# STM32L053x register map
File version: 1.0
Registers are 32-bit, read-write, reset 0x0 unless marked. A register's access mark holds for its fields unless they carry their own. Offsets are from the block's base; [hi:lo] are bit positions; lines under a group give offsets from that group; {n}, {i} and the like mark numbered series; 'fields as' and 'values as' point back to an identical list.

## LCD — Liquid crystal display controller
Base 0x40002400
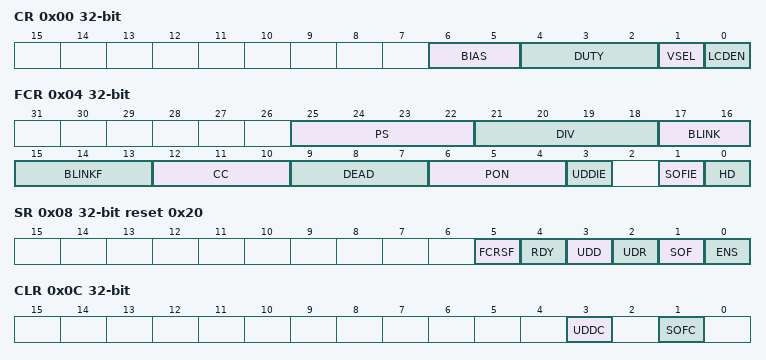
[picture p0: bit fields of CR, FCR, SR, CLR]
0x00 CR — control register
  [6:5] BIAS — Bias selector
  [4:2] DUTY — Duty selection
  [1] VSEL — Voltage source selection
  [0] LCDEN — LCD controller enable
0x04 FCR — frame control register
  [25:22] PS — PS 16-bit prescaler
  [21:18] DIV — DIV clock divider
  [17:16] BLINK — Blink mode selection
  [15:13] BLINKF — Blink frequency selection
  [12:10] CC — Contrast control
  [9:7] DEAD — Dead time duration
  [6:4] PON — Pulse ON duration
  [3] UDDIE — Update display done interrupt enable
  [1] SOFIE — Start of frame interrupt enable
  [0] HD — High drive enable
0x08 SR access per field reset 0x20 — status register
  [5] FCRSF ro — LCD Frame Control Register Synchronization flag
  [4] RDY ro — Ready flag
  [3] UDD ro — Update Display Done
  [2] UDR wo — Update display request
  [1] SOF ro — Start of frame flag
  [0] ENS ro
0x0C CLR wo — clear register
  [3] UDDC — Update display done clear
  [1] SOFC — Start of frame flag clear
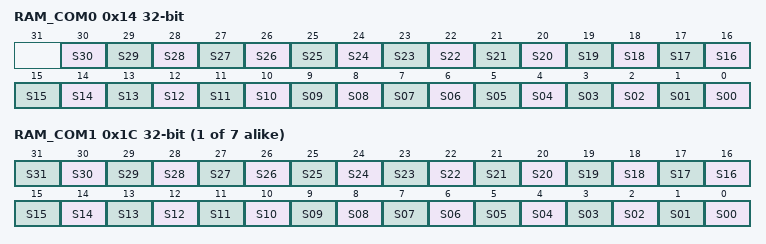
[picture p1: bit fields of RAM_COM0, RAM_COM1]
0x14 RAM_COM0 — display memory
  [n] S{n:02} (n=0..30)
{0x14+8i} RAM_COM{i} (i=1..7) — display memory
  [n] S{n:02} (n=0..31)

## LPTIM — Low power timer
Base 0x40007C00
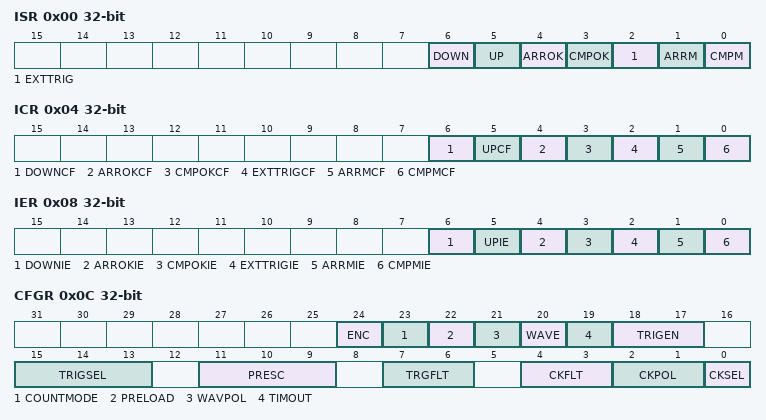
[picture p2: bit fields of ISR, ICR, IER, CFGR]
0x00 ISR ro — Interrupt and Status Register
  [6] DOWN — Counter direction change up to down
  [5] UP — Counter direction change down to up
  [4] ARROK — Autoreload register update OK
  [3] CMPOK — Compare register update OK
  [2] EXTTRIG — External trigger edge event
  [1] ARRM — Autoreload match
  [0] CMPM — Compare match
0x04 ICR wo — Interrupt Clear Register
  [6] DOWNCF — Direction change to down Clear Flag
  [5] UPCF — Direction change to UP Clear Flag
  [4] ARROKCF — Autoreload register update OK Clear Flag
  [3] CMPOKCF — Compare register update OK Clear Flag
  [2] EXTTRIGCF — External trigger valid edge Clear Flag
  [1] ARRMCF — Autoreload match Clear Flag
  [0] CMPMCF — compare match Clear Flag
0x08 IER — Interrupt Enable Register
  [6] DOWNIE — Direction change to down Interrupt Enable
  [5] UPIE — Direction change to UP Interrupt Enable
  [4] ARROKIE — Autoreload register update OK Interrupt Enable
  [3] CMPOKIE — Compare register update OK Interrupt Enable
  [2] EXTTRIGIE — External trigger valid edge Interrupt Enable
  [1] ARRMIE — Autoreload match Interrupt Enable
  [0] CMPMIE — Compare match Interrupt Enable
0x0C CFGR — Configuration Register
  [24] ENC — Encoder mode enable
  [23] COUNTMODE — counter mode enabled
  [22] PRELOAD — Registers update mode
  [21] WAVPOL — Waveform shape polarity
  [20] WAVE — Waveform shape
  [19] TIMOUT — Timeout enable
  [18:17] TRIGEN — Trigger enable and polarity
  [15:13] TRIGSEL — Trigger selector
  [11:9] PRESC — Clock prescaler
  [7:6] TRGFLT — Configurable digital filter for trigger
  [4:3] CKFLT — Configurable digital filter for external clock
  [2:1] CKPOL — Clock Polarity
  [0] CKSEL — Clock selector
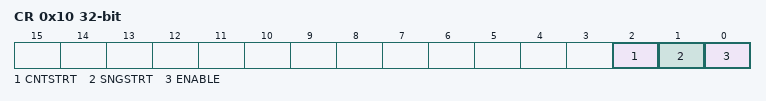
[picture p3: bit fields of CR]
0x10 CR — Control Register
  [2] CNTSTRT — Timer start in continuous mode
  [1] SNGSTRT — LPTIM start in single mode
  [0] ENABLE — LPTIM Enable
0x14 CMP — Compare Register
  [15:0] CMP — Compare value.
0x18 ARR reset 0x1 — Autoreload Register
  [15:0] ARR — Auto reload value.
0x1C CNT ro — Counter Register
  [15:0] CNT — Counter value.

## RNG — Random number generator
Base 0x40025000
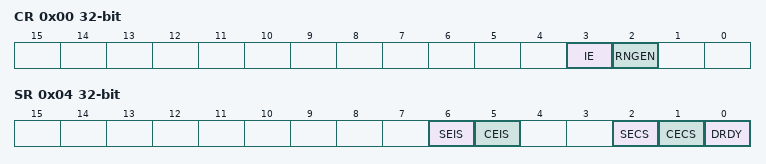
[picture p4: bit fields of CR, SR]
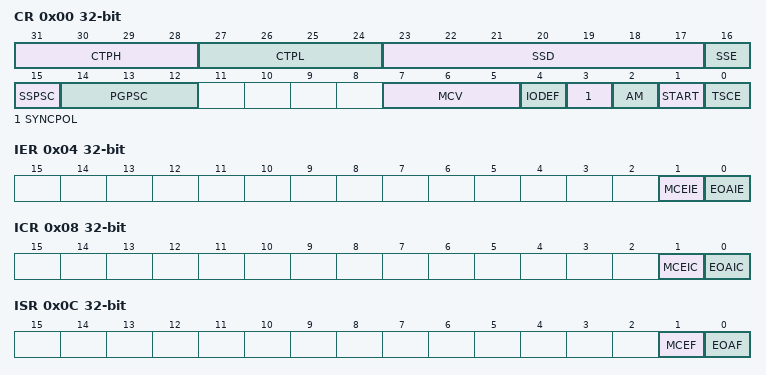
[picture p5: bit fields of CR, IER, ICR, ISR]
0x00 CR — control register
  [3] IE — Interrupt enable
  [2] RNGEN — Random number generator enable
0x04 SR access per field — status register
  [6] SEIS rw — Seed error interrupt status
  [5] CEIS rw — Clock error interrupt status
  [2] SECS ro — Seed error current status
  [1] CECS ro — Clock error current status
  [0] DRDY ro — Data ready
0x08 DR ro — data register
  [31:0] RNDATA — Random data

## TSC — Touch sensing controller
Base 0x40024000
0x00 CR — control register
  [31:28] CTPH — Charge transfer pulse high
  [27:24] CTPL — Charge transfer pulse low
  [23:17] SSD — Spread spectrum deviation
  [16] SSE — Spread spectrum enable
  [15] SSPSC — Spread spectrum prescaler
  [14:12] PGPSC — pulse generator prescaler
  [7:5] MCV — Max count value
  [4] IODEF — I/O Default mode
  [3] SYNCPOL — Synchronization pin polarity
  [2] AM — Acquisition mode
  [1] START — Start a new acquisition
  [0] TSCE — Touch sensing controller enable
0x04 IER — interrupt enable register
  [1] MCEIE — Max count error interrupt enable
  [0] EOAIE — End of acquisition interrupt enable
0x08 ICR — interrupt clear register
  [1] MCEIC — Max count error interrupt clear
  [0] EOAIC — End of acquisition interrupt clear
0x0C ISR — interrupt status register
  [1] MCEF — Max count error flag
  [0] EOAF — End of acquisition flag
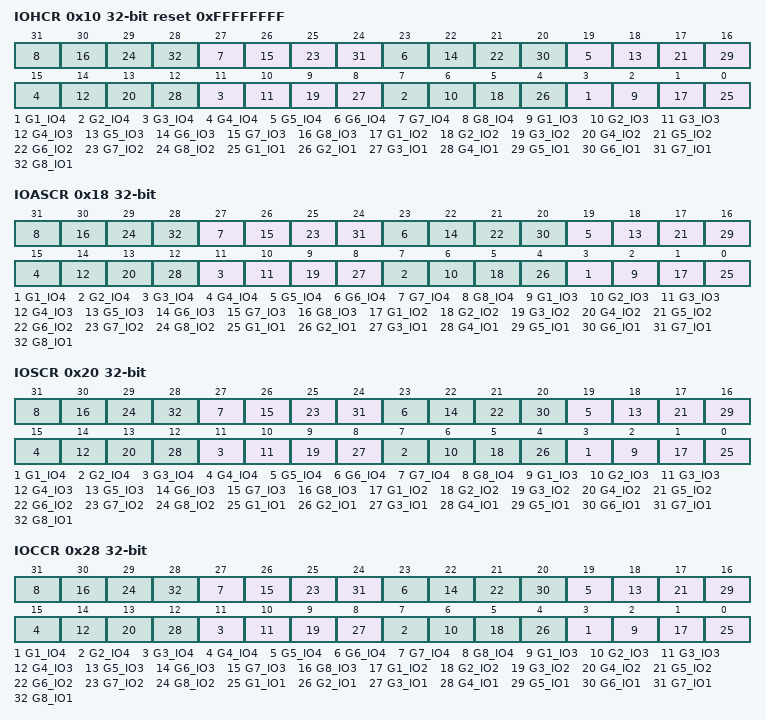
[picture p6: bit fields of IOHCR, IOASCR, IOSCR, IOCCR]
0x10 IOHCR reset 0xFFFFFFFF — I/O hysteresis control register
  [4n-1] G{n}_IO4 (n=1..8), [4n-2] G{n}_IO3 (n=1..8), [4n-3] G{n}_IO2 (n=1..8), [4n-4] G{n}_IO1 (n=1..8)
0x18 IOASCR — I/O analog switch control register
  fields as IOHCR
0x20 IOSCR — I/O sampling control register
  fields as IOHCR
0x28 IOCCR — I/O channel control register
  fields as IOHCR
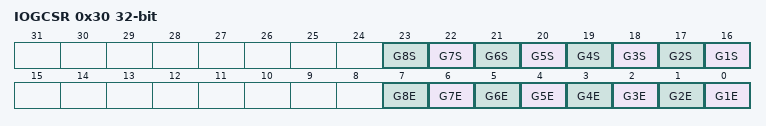
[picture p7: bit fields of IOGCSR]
0x30 IOGCSR access per field — I/O group control status register
  [n+15] G{n}S ro (n=1..8) — Analog I/O group x status
  [n-1] G{n}E rw (n=1..8) — Analog I/O group x enable
{0x30+4i} IOG{i}CR ro (i=1..8) — I/O group x counter register
  [13:0] CNT — Counter value
